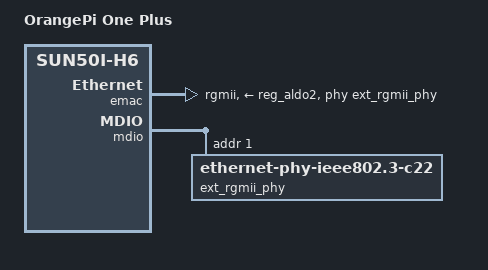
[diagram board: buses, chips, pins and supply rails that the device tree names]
// SPDX-License-Identifier: (GPL-2.0+ or MIT)
/*
 * Copyright (C) 2018 Amarula Solutions
 * Author: Jagan Teki <jagan@amarulasolutions.com>
 */

#include "sun50i-h6-orangepi.dtsi"

/ {
	model = "OrangePi One Plus";
	compatible = "xunlong,orangepi-one-plus", "allwinner,sun50i-h6";

	aliases {
		serial0 = &uart0;
		ethernet0 = &emac;
	};
};

&emac {
	pinctrl-names = "default";
	pinctrl-0 = <&ext_rgmii_pins>;
	phy-mode = "rgmii";
	phy-handle = <&ext_rgmii_phy>;
	phy-supply = <&reg_aldo2>;
	allwinner,rx-delay-ps = <200>;
	allwinner,tx-delay-ps = <200>;
	status = "okay";
};

&mdio {
	ext_rgmii_phy: ethernet-phy@1 {
		compatible = "ethernet-phy-ieee802.3-c22";
		reg = <1>;
	};
};
